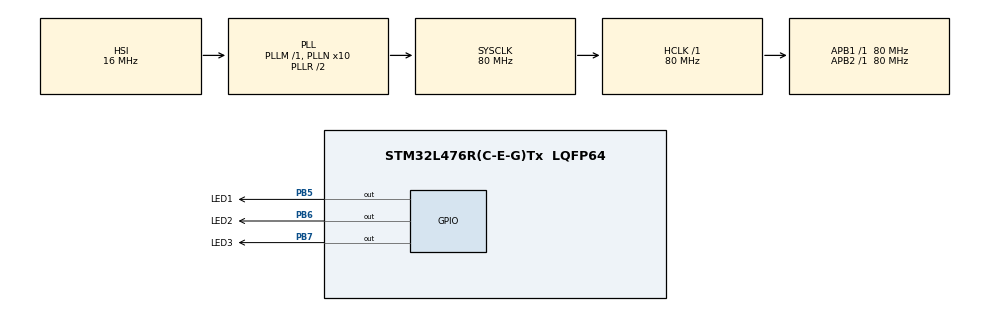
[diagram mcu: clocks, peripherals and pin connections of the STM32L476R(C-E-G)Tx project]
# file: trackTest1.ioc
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FREERTOS.Tasks01=defaultTask,0,128,StartDefaultTask,Default,NULL,Dynamic,NULL,NULL;ledControlTask,0,128,ledcontrol,Default,NULL,Dynamic,NULL,NULL
FREERTOS.configTOTAL_HEAP_SIZE=32000
FREERTOS.configUSE_TRACE_FACILITY=1
Mcu.Family=STM32L4
Mcu.Name=STM32L476R(C-E-G)Tx
Mcu.Package=LQFP64
NVIC.PriorityGroup=NVIC_PRIORITYGROUP_4
NVIC.TIM1_UP_TIM16_IRQn=true\:0\:0\:false\:false\:true\:false\:false
NVIC.TimeBase=TIM1_UP_TIM16_IRQn
NVIC.TimeBaseIP=TIM1
PA13\ (JTMS-SWDIO).Mode=Trace_Asynchronous_SW
PA13\ (JTMS-SWDIO).Signal=SYS_JTMS-SWDIO
PA14\ (JTCK-SWCLK).Mode=Trace_Asynchronous_SW
PA14\ (JTCK-SWCLK).Signal=SYS_JTCK-SWCLK
PB3\ (JTDO-TRACESWO).Mode=Trace_Asynchronous_SW
PB3\ (JTDO-TRACESWO).Signal=SYS_JTDO-SWO
PB5.GPIO_Label=LED1
PB5.GPIO_ModeDefaultOutputPP=GPIO_MODE_OUTPUT_PP
PB5.PinState=GPIO_PIN_RESET
PB5.Signal=GPIO_Output
PB6.GPIO_Label=LED2
PB6.Signal=GPIO_Output
PB7.GPIO_Label=LED3
PB7.Signal=GPIO_Output
PC14-OSC32_IN\ (PC14).Mode=LSE-External-Oscillator
PC14-OSC32_IN\ (PC14).Signal=RCC_OSC32_IN
PC15-OSC32_OUT\ (PC15).Mode=LSE-External-Oscillator
PC15-OSC32_OUT\ (PC15).Signal=RCC_OSC32_OUT
PH0-OSC_IN\ (PH0).Mode=HSE-External-Oscillator
PH0-OSC_IN\ (PH0).Signal=RCC_OSC_IN
PH1-OSC_OUT\ (PH1).Mode=HSE-External-Oscillator
PH1-OSC_OUT\ (PH1).Signal=RCC_OSC_OUT
ProjectManager.HeapSize=0x200
ProjectManager.StackSize=0x400
ProjectManager.TargetToolchain=SW4STM32
RCC.ADCFreq_Value=64000000
RCC.AHBFreq_Value=80000000
RCC.APB1Freq_Value=80000000
RCC.APB1TimFreq_Value=80000000
RCC.APB2Freq_Value=80000000
RCC.APB2TimFreq_Value=80000000
RCC.CortexFreq_Value=80000000
RCC.HCLKFreq_Value=80000000
RCC.HSE_VALUE=16000000
RCC.HSI_VALUE=16000000
RCC.MSI_VALUE=4000000
RCC.PLLN=10
RCC.PLLSourceVirtual=RCC_PLLSOURCE_HSI
RCC.SYSCLKFreq_VALUE=80000000
RCC.SYSCLKSource=RCC_SYSCLKSOURCE_PLLCLK
RCC.USBFreq_Value=64000000
RCC.VCOOutputFreq_Value=160000000
VP_FREERTOS_VS_ENABLE.Mode=Enabled
VP_SYS_VS_tim1.Mode=TIM1
board=trackTest1

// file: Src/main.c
/**
 ******************************************************************************
 * File Name          : main.c
 * Description        : Main program body
 ******************************************************************************
 * This notice applies to any and all portions of this file
 * that are not between comment pairs USER CODE BEGIN and
 * USER CODE END. Other portions of this file, whether
 * inserted by the user or by software development tools
 * are owned by their respective copyright owners.
 *
 * Copyright (c) 2018 STMicroelectronics International N.V.
 * All rights reserved.
 *
 * Redistribution and use in source and binary forms, with or without
 * modification, are permitted, provided that the following conditions are met:
 *
 * 1. Redistribution of source code must retain the above copyright notice,
 *    this list of conditions and the following disclaimer.
 * 2. Redistributions in binary form must reproduce the above copyright notice,
 *    this list of conditions and the following disclaimer in the documentation
 *    and/or other materials provided with the distribution.
 * 3. Neither the name of STMicroelectronics nor the names of other
 *    contributors to this software may be used to endorse or promote products
 *    derived from this software without specific written permission.
 * 4. This software, including modifications and/or derivative works of this
 *    software, must execute solely and exclusively on microcontroller or
 *    microprocessor devices manufactured by or for STMicroelectronics.
 * 5. Redistribution and use of this software other than as permitted under
 *    this license is void and will automatically terminate your rights under
 *    this license.
 *
 * THIS SOFTWARE IS PROVIDED BY STMICROELECTRONICS AND CONTRIBUTORS "AS IS"
 * AND ANY EXPRESS, IMPLIED OR STATUTORY WARRANTIES, INCLUDING, BUT NOT
 * LIMITED TO, THE IMPLIED WARRANTIES OF MERCHANTABILITY, FITNESS FOR A
 * PARTICULAR PURPOSE AND NON-INFRINGEMENT OF THIRD PARTY INTELLECTUAL PROPERTY
 * RIGHTS ARE DISCLAIMED TO THE FULLEST EXTENT PERMITTED BY LAW. IN NO EVENT
 * SHALL STMICROELECTRONICS OR CONTRIBUTORS BE LIABLE FOR ANY DIRECT, INDIRECT,
 * INCIDENTAL, SPECIAL, EXEMPLARY, OR CONSEQUENTIAL DAMAGES (INCLUDING, BUT NOT
 * LIMITED TO, PROCUREMENT OF SUBSTITUTE GOODS OR SERVICES; LOSS OF USE, DATA,
 * OR PROFITS; OR BUSINESS INTERRUPTION) HOWEVER CAUSED AND ON ANY THEORY OF
 * LIABILITY, WHETHER IN CONTRACT, STRICT LIABILITY, OR TORT (INCLUDING
 * NEGLIGENCE OR OTHERWISE) ARISING IN ANY WAY OUT OF THE USE OF THIS SOFTWARE,
 * EVEN IF ADVISED OF THE POSSIBILITY OF SUCH DAMAGE.
 *
 ******************************************************************************
 */

#include "main.h"
#include "stm32l4xx_hal.h"
#include "cmsis_os.h"

/* USER CODE BEGIN Includes */
#include "SEGGER_SYSVIEW.h"
/* USER CODE END Includes */

osThreadId defaultTaskHandle;
osThreadId ledControlTaskHandle;

/* USER CODE BEGIN PV */
/* Private variables ---------------------------------------------------------*/

/* USER CODE END PV */

void SystemClock_Config(void);
static void MX_GPIO_Init(void);
void StartDefaultTask(void const * argument);
void ledcontrol(void const * argument);

/* USER CODE BEGIN PFP */
/* Private function prototypes -----------------------------------------------*/

/* USER CODE END PFP */

int main(void)
{

	/* MCU Configuration----------------------------------------------------------*/

	/* Reset of all peripherals, Initializes the Flash interface and the Systick. */
	HAL_Init();

	/* Configure the system clock */
	SystemClock_Config();

	/* Initialize all configured peripherals */
	MX_GPIO_Init();

	/* USER CODE BEGIN 2 */
	//	SEGGER_SYSVIEW_Init(1000, 80000000, 0, 0);
	//	    SEGGER_SYSVIEW_Start();
	SEGGER_SYSVIEW_Conf();
	/* USER CODE END 2 */

	/* Create the thread(s) */
	/* definition and creation of defaultTask */
	osThreadDef(defaultTask, StartDefaultTask, osPriorityNormal, 0, 128);
	defaultTaskHandle = osThreadCreate(osThread(defaultTask), NULL);

	/* definition and creation of ledControlTask */
	osThreadDef(ledControlTask, ledcontrol, osPriorityNormal, 0, 128);
	ledControlTaskHandle = osThreadCreate(osThread(ledControlTask), NULL);

	/* Start scheduler */
	osKernelStart();

	/* We should never get here as control is now taken by the scheduler */

	/* Infinite loop */
	while (1)
	{

	}

}

/** System Clock Configuration
 */
void SystemClock_Config(void)
{

	RCC_OscInitTypeDef RCC_OscInitStruct;
	RCC_ClkInitTypeDef RCC_ClkInitStruct;

	/**Initializes the CPU, AHB and APB busses clocks
	 */
	RCC_OscInitStruct.OscillatorType = RCC_OSCILLATORTYPE_HSI;
	RCC_OscInitStruct.HSIState = RCC_HSI_ON;
	RCC_OscInitStruct.HSICalibrationValue = 16;
	RCC_OscInitStruct.PLL.PLLState = RCC_PLL_ON;
	RCC_OscInitStruct.PLL.PLLSource = RCC_PLLSOURCE_HSI;
	RCC_OscInitStruct.PLL.PLLM = 1;
	RCC_OscInitStruct.PLL.PLLN = 10;
	RCC_OscInitStruct.PLL.PLLP = RCC_PLLP_DIV7;
	RCC_OscInitStruct.PLL.PLLQ = RCC_PLLQ_DIV2;
	RCC_OscInitStruct.PLL.PLLR = RCC_PLLR_DIV2;
	if (HAL_RCC_OscConfig(&RCC_OscInitStruct) != HAL_OK)
	{
		_Error_Handler(__FILE__, __LINE__);
	}

	/**Initializes the CPU, AHB and APB busses clocks
	 */
	RCC_ClkInitStruct.ClockType = RCC_CLOCKTYPE_HCLK|RCC_CLOCKTYPE_SYSCLK
			|RCC_CLOCKTYPE_PCLK1|RCC_CLOCKTYPE_PCLK2;
	RCC_ClkInitStruct.SYSCLKSource = RCC_SYSCLKSOURCE_PLLCLK;
	RCC_ClkInitStruct.AHBCLKDivider = RCC_SYSCLK_DIV1;
	RCC_ClkInitStruct.APB1CLKDivider = RCC_HCLK_DIV1;
	RCC_ClkInitStruct.APB2CLKDivider = RCC_HCLK_DIV1;

	if (HAL_RCC_ClockConfig(&RCC_ClkInitStruct, FLASH_LATENCY_3) != HAL_OK)
	{
		_Error_Handler(__FILE__, __LINE__);
	}

	/**Configure the main internal regulator output voltage
	 */
	if (HAL_PWREx_ControlVoltageScaling(PWR_REGULATOR_VOLTAGE_SCALE1) != HAL_OK)
	{
		_Error_Handler(__FILE__, __LINE__);
	}

	/**Configure the Systick interrupt time
	 */
	HAL_SYSTICK_Config(HAL_RCC_GetHCLKFreq()/1000);

	/**Configure the Systick
	 */
	HAL_SYSTICK_CLKSourceConfig(SYSTICK_CLKSOURCE_HCLK);

	/* SysTick_IRQn interrupt configuration */
	HAL_NVIC_SetPriority(SysTick_IRQn, 15, 0);
}

/** Configure pins as
 * Analog
 * Input
 * Output
 * EVENT_OUT
 * EXTI
 */
static void MX_GPIO_Init(void)
{

	GPIO_InitTypeDef GPIO_InitStruct;

	/* GPIO Ports Clock Enable */
	__HAL_RCC_GPIOC_CLK_ENABLE();
	__HAL_RCC_GPIOH_CLK_ENABLE();
	__HAL_RCC_GPIOA_CLK_ENABLE();
	__HAL_RCC_GPIOB_CLK_ENABLE();

	/*Configure GPIO pin Output Level */
	HAL_GPIO_WritePin(GPIOB, LED1_Pin|LED2_Pin|LED3_Pin, GPIO_PIN_RESET);

	/*Configure GPIO pins : LED1_Pin LED2_Pin LED3_Pin */
	GPIO_InitStruct.Pin = LED1_Pin|LED2_Pin|LED3_Pin;
	GPIO_InitStruct.Mode = GPIO_MODE_OUTPUT_PP;
	GPIO_InitStruct.Pull = GPIO_NOPULL;
	GPIO_InitStruct.Speed = GPIO_SPEED_FREQ_LOW;
	HAL_GPIO_Init(GPIOB, &GPIO_InitStruct);

}

/* StartDefaultTask function */
void StartDefaultTask(void const * argument)
{

	for(;;)
	{
		osDelay(1);
	}
}

/* ledcontrol function */
void ledcontrol(void const * argument)
{
	/* USER CODE BEGIN ledcontrol */
	/* Infinite loop */
	for(;;)
	{
		HAL_GPIO_TogglePin(LED1_GPIO_Port,LED1_Pin);
		osDelay(500);
	}
	/* USER CODE END ledcontrol */
}

void HAL_TIM_PeriodElapsedCallback(TIM_HandleTypeDef *htim)
{
	if (htim->Instance == TIM1) {
		HAL_IncTick();
	}
}

void _Error_Handler(char * file, int line)
{
	while(1)
	{
	}
}

/************************ (C) COPYRIGHT STMicroelectronics *****END OF FILE****/
